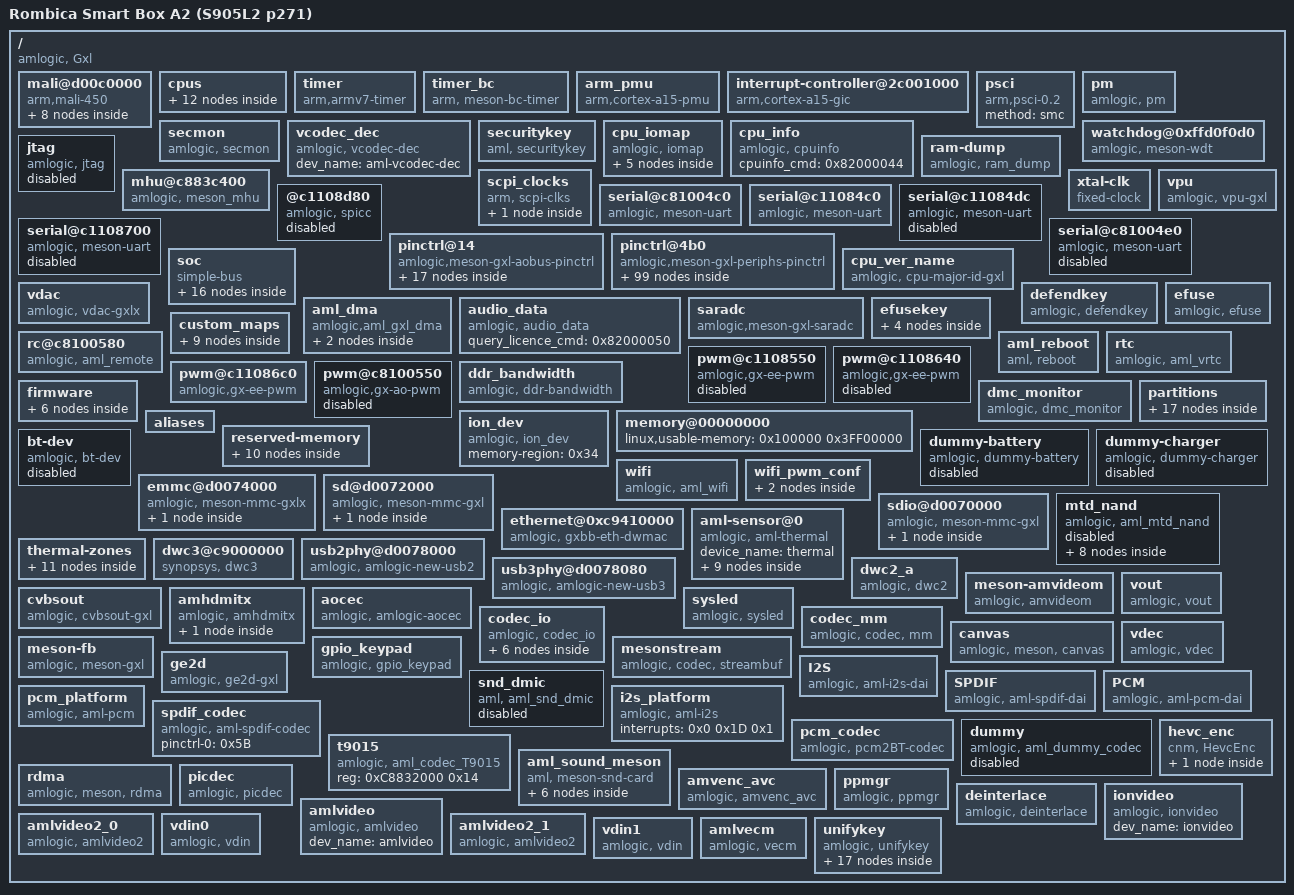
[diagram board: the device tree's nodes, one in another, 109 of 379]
/dts-v1/;
// version: 17
// last_comp_version: 16
// boot_cpuid_phys: 0x0

/ {
    amlogic-dt-id = "gxl_p212_1g";
    compatible = "amlogic, Gxl";
    interrupt-parent = <0x1>;
    #address-cells = <0x1>;
    #size-cells = <0x1>;
    model = "Rombica Smart Box A2 (S905L2 p271)";
    mali@d00c0000 {
        #cooling-cells = <0x2>;
        compatible = "arm,mali-450";
        interrupt-parent = <0x1>;
        reg = <0xD00C0000 0x40000 0xC1104440 0x1000 0xC8100000 0x1000 0xC883C000 0x1000 0xC1104440 0x1000>;
        pmu_switch_delay = <0xFFFF>;
        clocks = <0x8 0x97 0x8 0x9>;
        clock-names = "gpu_mux", "gp0_pll";
        control_interval = <0xC8>;
        phandle = <0x80>;
        num_of_pp = <0x2>;
        sc_mpp = <0x2>;
        pmu_domain_config = <0x1 0x2 0x4 0x0 0x0 0x0 0x0 0x0 0x0 0x1 0x2 0x0>;
        tbl = <0x2 0x3 0x4 0x5 0x6 0x6>;
        interrupts = <0x0 0xA0 0x4 0x0 0xA1 0x4 0x0 0xA2 0x4 0x0 0xA3 0x4 0x0 0xA4 0x4 0x0 0xA5 0x4 0x0 0xA6 0x4 0x0 0xA7 0x4>;
        interrupt-names = "IRQGP", "IRQGPMMU", "IRQPP", "IRQPMU", "IRQPP0", "IRQPPMMU0", "IRQPP1", "IRQPPMMU1";
        def_clk = <0x3>;
        clk125_cfg {
            clk_freq = <0x7735940>;
            clk_parent = "fclk_div4";
            clkp_freq = <0x1DCD6500>;
            voltage = <0x47E>;
            keep_count = <0x5>;
            threshold = <0x1E 0xFA>;
            phandle = <0x2>;
        };
        clk250_cfg {
            clk_freq = <0xEE6B280>;
            clk_parent = "fclk_div4";
            clkp_freq = <0x1DCD6500>;
            voltage = <0x47E>;
            keep_count = <0x5>;
            threshold = <0x73 0xFA>;
            phandle = <0x81>;
        };
        clk285_cfg {
            clk_freq = <0x1107A76D>;
            clk_parent = "fclk_div7";
            clkp_freq = <0x1107A76D>;
            voltage = <0x47E>;
            keep_count = <0x5>;
            threshold = <0x64 0xFA>;
            phandle = <0x3>;
        };
        clk400_cfg {
            clk_freq = <0x17D78400>;
            clk_parent = "fclk_div5";
            clkp_freq = <0x17D78400>;
            voltage = <0x47E>;
            keep_count = <0x3>;
            threshold = <0xA8 0xFA>;
            phandle = <0x4>;
        };
        clk500_cfg {
            clk_freq = <0x1DCD6500>;
            clk_parent = "fclk_div4";
            clkp_freq = <0x1DCD6500>;
            voltage = <0x47E>;
            keep_count = <0x2>;
            threshold = <0xBE 0xFA>;
            phandle = <0x5>;
        };
        clk666_cfg {
            clk_freq = <0x27BC86AA>;
            clk_parent = "fclk_div3";
            clkp_freq = <0x27BC86AA>;
            voltage = <0x47E>;
            keep_count = <0x1>;
            threshold = <0xB1 0xFA>;
            phandle = <0x6>;
        };
        clk750_cfg {
            clk_freq = <0x2C588A00>;
            clk_parent = "gp0_pll";
            clkp_freq = <0x2C588A00>;
            voltage = <0x47E>;
            keep_count = <0x1>;
            threshold = <0xD5 0xFF>;
            phandle = <0x7>;
        };
        clk800_cfg {
            clk_freq = <0x2F34F600>;
            clk_parent = "gp0_pll";
            clkp_freq = <0x2F34F600>;
            voltage = <0x47E>;
            keep_count = <0x1>;
            threshold = <0xE6 0xFF>;
            phandle = <0x82>;
        };
    };
    cpus {
        #address-cells = <0x1>;
        #size-cells = <0x0>;
        phandle = <0x83>;
        cpu-map {
            cluster0 {
                phandle = <0x84>;
                core0 {
                    cpu = <0x9>;
                };
                core1 {
                    cpu = <0xA>;
                };
                core2 {
                    cpu = <0xB>;
                };
                core3 {
                    cpu = <0xC>;
                };
            };
        };
        cpu@0 {
            device_type = "cpu";
            compatible = "arm,cortex-a53", "arm,armv8";
            reg = <0x0>;
            enable-method = "psci";
            clocks = <0xD 0x0>;
            clock-names = "cpu-cluster.0";
            cpu-idle-states = <0xE>;
            phandle = <0x9>;
        };
        cpu@1 {
            device_type = "cpu";
            compatible = "arm,cortex-a53", "arm,armv8";
            reg = <0x1>;
            enable-method = "psci";
            clocks = <0xD 0x0>;
            clock-names = "cpu-cluster.0";
            cpu-idle-states = <0xE>;
            phandle = <0xA>;
        };
        cpu@2 {
            device_type = "cpu";
            compatible = "arm,cortex-a53", "arm,armv8";
            reg = <0x2>;
            enable-method = "psci";
            clocks = <0xD 0x0>;
            clock-names = "cpu-cluster.0";
            cpu-idle-states = <0xE>;
            phandle = <0xB>;
        };
        cpu@3 {
            device_type = "cpu";
            compatible = "arm,cortex-a53", "arm,armv8";
            reg = <0x3>;
            enable-method = "psci";
            clocks = <0xD 0x0>;
            clock-names = "cpu-cluster.0";
            cpu-idle-states = <0xE>;
            phandle = <0xC>;
        };
        idle-states {
            entry-method = "arm,psci";
            system-sleep-0 {
                compatible = "arm,idle-state";
                arm,psci-suspend-param = <0x20000>;
                local-timer-stop;
                entry-latency-us = <0x3FFFFFFF>;
                exit-latency-us = <0x40000000>;
                min-residency-us = <0xFFFFFFFF>;
                phandle = <0xE>;
            };
        };
    };
    timer {
        compatible = "arm,armv7-timer";
        interrupts = <0x1 0xD 0xFF08 0x1 0xE 0xFF08 0x1 0xB 0xFF08 0x1 0xA 0xFF08>;
    };
    timer_bc {
        compatible = "arm, meson-bc-timer";
        reg = <0xC1109990 0x4 0xC1109994 0x4>;
        timer_name = "Meson TimerF";
        clockevent-rating = <0x12C>;
        clockevent-shift = <0x14>;
        clockevent-features = <0x23>;
        interrupts = <0x0 0x3C 0x1>;
        bit_enable = <0x10>;
        bit_mode = <0xC>;
        bit_resolution = <0x0>;
    };
    arm_pmu {
        compatible = "arm,cortex-a15-pmu";
        interrupts = <0x0 0x89 0x4>;
        reg = <0xC8834680 0x4>;
        cpumasks = <0xF>;
        relax-timer-ns = <0x989680>;
        max-wait-cnt = <0x2710>;
    };
    interrupt-controller@2c001000 {
        compatible = "arm,cortex-a15-gic", "arm,cortex-a9-gic";
        #interrupt-cells = <0x3>;
        #address-cells = <0x0>;
        interrupt-controller;
        reg = <0xC4301000 0x1000 0xC4302000 0x100>;
        interrupts = <0x1 0x9 0xF04>;
        phandle = <0x1>;
    };
    psci {
        compatible = "arm,psci-0.2";
        method = "smc";
    };
    pm {
        compatible = "amlogic, pm";
        device_name = "aml_pm";
        reg = <0xC81000A8 0x4 0xC810023C 0x4>;
        phandle = <0x85>;
    };
    secmon {
        compatible = "amlogic, secmon";
        memory-region = <0xF>;
        in_base_func = <0x82000020>;
        out_base_func = <0x82000021>;
        reserve_mem_size = <0x300000>;
    };
    vcodec_dec {
        compatible = "amlogic, vcodec-dec";
        dev_name = "aml-vcodec-dec";
        status = "okay";
    };
    securitykey {
        compatible = "aml, securitykey";
        storage_query = <0x82000060>;
        storage_read = <0x82000061>;
        storage_write = <0x82000062>;
        storage_tell = <0x82000063>;
        storage_verify = <0x82000064>;
        storage_status = <0x82000065>;
        storage_list = <0x82000067>;
        storage_remove = <0x82000068>;
        storage_in_func = <0x82000023>;
        storage_out_func = <0x82000024>;
        storage_block_func = <0x82000025>;
        storage_size_func = <0x82000027>;
        storage_set_enctype = <0x8200006A>;
        storage_get_enctype = <0x8200006B>;
        storage_version = <0x8200006C>;
    };
    cpu_iomap {
        compatible = "amlogic, iomap";
        #address-cells = <0x1>;
        #size-cells = <0x1>;
        ranges;
        io_cbus_base {
            reg = <0xC1100000 0x100000>;
        };
        io_apb_base {
            reg = <0xD0050000 0x50000>;
        };
        io_aobus_base {
            reg = <0xC8100000 0x100000>;
        };
        io_vapb_base {
            reg = <0xD0100000 0x100000>;
        };
        io_hiu_base {
            reg = <0xC883C000 0x2000>;
        };
    };
    cpu_info {
        compatible = "amlogic, cpuinfo";
        cpuinfo_cmd = <0x82000044>;
        status = "okay";
    };
    watchdog@0xffd0f0d0 {
        compatible = "amlogic, meson-wdt";
        status = "okay";
        default_timeout = <0xA>;
        reset_watchdog_method = <0x1>;
        reset_watchdog_time = <0x2>;
        shutdown_timeout = <0xA>;
        firmware_timeout = <0x6>;
        suspend_timeout = <0x6>;
        reg = <0xC11098D0 0x10>;
        clock-names = "xtal";
        clocks = <0x10>;
        phandle = <0x86>;
    };
    ram-dump {
        compatible = "amlogic, ram_dump";
        status = "okay";
    };
    jtag {
        compatible = "amlogic, jtag";
        select = "apao";
        jtagao-gpios = <0x11 0x16 0x0 0x11 0x17 0x0 0x11 0x18 0x0 0x11 0x19 0x0>;
        jtagee-gpios = <0x11 0x2A 0x0 0x11 0x2B 0x0 0x11 0x2C 0x0 0x11 0x2D 0x0>;
        status = "disabled";
    };
    mhu@c883c400 {
        compatible = "amlogic, meson_mhu";
        reg = <0xC883C400 0x4C 0xC8013000 0x800>;
        interrupts = <0x0 0xD1 0x1 0x0 0xD2 0x1>;
        #mbox-cells = <0x1>;
        mbox-names = "cpu_to_scp_low", "cpu_to_scp_high";
        mboxes = <0x12 0x0 0x12 0x1>;
        phandle = <0x12>;
    };
    scpi_clocks {
        compatible = "arm, scpi-clks";
        scpi_clocks@0 {
            compatible = "arm, scpi-clk-indexed";
            #clock-cells = <0x1>;
            clock-indices = <0x0>;
            clock-output-names = "vcpu";
            phandle = <0xD>;
        };
    };
    xtal-clk {
        compatible = "fixed-clock";
        clock-frequency = <0x16E3600>;
        clock-output-names = "xtal";
        #clock-cells = <0x0>;
        phandle = <0x10>;
    };
    vpu {
        compatible = "amlogic, vpu-gxl";
        dev_name = "vpu";
        status = "okay";
        clocks = <0x8 0xC4 0x8 0x59 0x8 0x9 0x8 0xB6 0x8 0xBA 0x8 0xBB>;
        clock-names = "vapb_clk", "vpu_intr_gate", "gp_pll", "vpu_clk0", "vpu_clk1", "vpu_clk";
        clk_level = <0x7>;
    };
    @c1108d80 {
        compatible = "amlogic, spicc";
        status = "disabled";
        reg = <0xC1108D80 0x28>;
        clocks = <0x8 0x1E>;
        clock-names = "spicc_clk";
        interrupts = <0x0 0x51 0x1>;
        device_id = <0x0>;
        pinctrl-names = "spicc_pulldown", "spicc_pullup";
        pinctrl-0 = <0x13>;
        pinctrl-1 = <0x14>;
        num_chipselect = <0x1>;
        cs-gpios = <0x11 0x59 0x0>;
        dma_en = <0x0>;
        dma_tx_threshold = <0x3>;
        dma_rx_threshold = <0x3>;
        dma_num_per_read_burst = <0x3>;
        dma_num_per_write_burst = <0x3>;
        delay_control = <0x15>;
        ssctl = <0x0>;
        phandle = <0x87>;
    };
    serial@c81004c0 {
        compatible = "amlogic, meson-uart";
        reg = <0xC81004C0 0x18>;
        interrupts = <0x0 0xC1 0x1>;
        status = "okay";
        clocks = <0x10>;
        clock-names = "clk_uart";
        xtal_tick_en = <0x1>;
        fifosize = <0x40>;
        pinctrl-names = "default";
        support-sysrq = <0x0>;
        phandle = <0x88>;
    };
    serial@c11084c0 {
        compatible = "amlogic, meson-uart";
        reg = <0xC11084C0 0x18>;
        interrupts = <0x0 0x1A 0x1>;
        status = "okay";
        clocks = <0x8 0x23>;
        clock-names = "clk_uart";
        fifosize = <0x80>;
        pinctrl-names = "default";
        pinctrl-0 = <0x15>;
        phandle = <0x89>;
    };
    serial@c11084dc {
        compatible = "amlogic, meson-uart";
        reg = <0xC11084DC 0x18>;
        interrupts = <0x0 0x4B 0x1>;
        status = "disabled";
        clocks = <0x8 0x40>;
        clock-names = "clk_uart";
        fifosize = <0x40>;
        pinctrl-names = "default";
        pinctrl-0 = <0x16>;
        phandle = <0x8A>;
    };
    serial@c1108700 {
        compatible = "amlogic, meson-uart";
        reg = <0xC1108700 0x18>;
        interrupts = <0x0 0x5D 0x1>;
        status = "disabled";
        clocks = <0x8 0x57>;
        clock-names = "clk_uart";
        fifosize = <0x40>;
        pinctrl-names = "default";
        pinctrl-0 = <0x17>;
        phandle = <0x8B>;
    };
    serial@c81004e0 {
        compatible = "amlogic, meson-uart";
        reg = <0xC81004E0 0x18>;
        interrupts = <0x0 0xC5 0x1>;
        status = "disable";
        clocks = <0x10>;
        clock-names = "clk_uart";
        fifosize = <0x40>;
        pinctrl-names = "default";
        pinctrl-0 = <0x18>;
        phandle = <0x8C>;
    };
    pinctrl@14 {
        compatible = "amlogic,meson-gxl-aobus-pinctrl";
        #address-cells = <0x1>;
        #size-cells = <0x1>;
        ranges;
        phandle = <0x8D>;
        bank@14 {
            reg = <0xC8100014 0x8 0xC810002C 0x4 0xC8100024 0x8>;
            reg-names = "mux", "pull", "gpio";
            gpio-controller;
            #gpio-cells = <0x2>;
            phandle = <0x57>;
        };
        remote_pin {
            phandle = <0x1E>;
            mux {
                groups = "remote_input";
                function = "remote";
            };
        };
        sd_to_ao_uart_clr_pins {
            phandle = <0x3E>;
            mux {
                groups = "GPIOAO_0", "GPIOAO_1";
                function = "gpio_aobus";
            };
        };
        sd_to_ao_uart_pins {
            phandle = <0x40>;
            mux {
                groups = "uart_tx_ao_a_0", "uart_rx_ao_a_0";
                function = "uart_ao";
                bias-pull-up;
                input-enable;
            };
        };
        ao_uart {
            phandle = <0x8E>;
            mux {
                groups = "uart_tx_ao_a_0", "uart_rx_ao_a_0";
                function = "uart_ao";
            };
        };
        ao_b_uart {
            phandle = <0x18>;
            mux {
                groups = "uart_tx_ao_b_0", "uart_rx_ao_b_0";
                function = "uart_ao_b";
            };
        };
        ao_i2c {
            phandle = <0x8F>;
            mux {
                groups = "i2c_sda_ao", "i2c_sck_ao";
                function = "i2c_ao";
            };
        };
        hdmitx_aocec {
            phandle = <0x54>;
            mux {
                groups = "ao_cec";
                function = "ao_cec";
            };
        };
        hdmitx_eecec {
            phandle = <0x90>;
            mux {
                groups = "ee_cec";
                function = "ee_cec";
            };
        };
    };
    pinctrl@4b0 {
        compatible = "amlogic,meson-gxl-periphs-pinctrl";
        #address-cells = <0x1>;
        #size-cells = <0x1>;
        ranges;
        phandle = <0x91>;
        bank@4b0 {
            reg = <0xC88344B0 0x28 0xC88344E8 0x14 0xC8834520 0x14 0xC8834430 0x40>;
            reg-names = "mux", "pull", "pull-enable", "gpio";
            gpio-controller;
            #gpio-cells = <0x2>;
            phandle = <0x11>;
        };
        external_eth_pins {
            phandle = <0x48>;
            mux {
                groups = "eth_mdio", "eth_mdc", "eth_clk_rx_clk", "eth_rx_dv", "eth_rxd0", "eth_rxd1", "eth_rxd2", "eth_rxd3", "eth_rgmii_tx_clk", "eth_tx_en", "eth_txd0", "eth_txd1", "eth_txd2", "eth_txd3";
                function = "eth";
            };
        };
        jtag_apao_pin {
            phandle = <0x92>;
            mux {
                groups = "jtag_tdi_0", "jtag_tdo_0", "jtag_clk_0", "jtag_tms_0";
                function = "jtag";
            };
        };
        jtag_apee_pin {
            phandle = <0x93>;
            mux {
                groups = "jtag_tdi_1", "jtag_tdo_1", "jtag_clk_1", "jtag_tms_1";
                function = "jtag";
            };
        };
        a_uart {
            phandle = <0x15>;
            mux {
                groups = "uart_tx_a", "uart_rx_a", "uart_cts_a", "uart_rts_a";
                function = "uart_a";
            };
        };
        b_uart {
            phandle = <0x16>;
            mux {
                groups = "uart_tx_b", "uart_rx_b", "uart_cts_b", "uart_rts_b";
                function = "uart_b";
            };
        };
        c_uart {
            phandle = <0x17>;
            mux {
                groups = "uart_tx_c", "uart_rx_c", "uart_cts_c", "uart_rts_c";
                function = "uart_c";
            };
        };
        wifi_32k_pins {
            phandle = <0x35>;
            mux {
                groups = "pwm_e";
                function = "pwm_e";
            };
        };
        ao_to_sd_uart_clr_pins {
            phandle = <0x94>;
            mux {
                groups = "sdcard_d2", "sdcard_d3";
                function = "sdcard";
                input-enable;
                bias-pull-up;
            };
        };
        sd_1bit_pins {
            phandle = <0x3D>;
            mux {
                groups = "sdcard_d0", "sdcard_cmd", "sdcard_clk";
                function = "sdcard";
                input-enable;
                bias-pull-up;
            };
        };
        ao_to_sd_uart_pins {
            phandle = <0x3F>;
            mux {
                groups = "uart_tx_ao_a_card4", "uart_rx_ao_a_card5";
                function = "uart_ao_a_card";
                bias-pull-up;
                input-enable;
            };
        };
        emmc_clk_cmd_pins {
            phandle = <0x38>;
            mux {
                groups = "emmc_cmd", "emmc_clk";
                function = "emmc";
                input-enable;
                bias-pull-up;
            };
        };
        emmc_conf_pull_up {
            phandle = <0x39>;
            mux {
                groups = "emmc_nand_d07", "emmc_clk", "emmc_cmd";
                function = "emmc";
                input-enable;
                bias-pull-up;
            };
        };
        emmc_conf_pull_done {
            phandle = <0x3A>;
            mux {
                groups = "emmc_ds";
                function = "emmc";
                input-enable;
                bias-pull-down;
            };
        };
        sd_clk_cmd_pins {
            phandle = <0x3C>;
            mux {
                groups = "sdcard_cmd", "sdcard_clk";
                function = "sdcard";
                input-enable;
                bias-pull-up;
            };
        };
        sd_all_pins {
            phandle = <0x3B>;
            mux {
                groups = "sdcard_d0", "sdcard_d1", "sdcard_d2", "sdcard_d3", "sdcard_cmd", "sdcard_clk";
                function = "sdcard";
                input-enable;
                bias-pull-up;
            };
        };
        sdio_clk_cmd_pins {
            phandle = <0x41>;
            mux {
                groups = "sdio_clk", "sdio_cmd";
                function = "sdio";
                input-enable;
                bias-pull-up;
            };
        };
        sdio_all_pins {
            phandle = <0x42>;
            mux {
                groups = "sdio_d0", "sdio_d1", "sdio_d2", "sdio_d3", "sdio_clk", "sdio_cmd";
                function = "sdio";
                input-enable;
                bias-pull-up;
            };
        };
        sd_iso7816_pins {
            phandle = <0x95>;
            mux {
                groups = "iso7816_clk_dv", "iso7816_data_dv";
                function = "iso7816";
                input-enable;
                bias-pull-down;
            };
        };
        nand_pulldown {
            phandle = <0x96>;
            mux {
                groups = "emmc_nand_d07", "emmc_ds";
                function = "emmc";
                bias-pull-down;
            };
        };
        nand_pullup {
            phandle = <0x97>;
            mux {
                groups = "emmc_clk", "emmc_cmd";
                function = "emmc";
                bias-pull-up;
            };
        };
        all_nand_pins {
            phandle = <0x43>;
            mux {
                groups = "emmc_nand_d07", "nand_ce0", "nand_ce1", "nand_rb0", "nand_ale", "nand_cle", "nand_wen_clk", "nand_ren_wr", "nand_dqs";
                function = "nand";
                input-enable;
            };
        };
        nand_cs {
            phandle = <0x44>;
            mux {
                groups = "nand_ce0", "nand_ce1";
                function = "nand";
            };
        };
        hdmitx_hpd {
            phandle = <0x52>;
            mux {
                groups = "hdmi_hpd";
                function = "hdmi_hpd";
            };
        };
        hdmitx_ddc {
            phandle = <0x53>;
            mux {
                groups = "hdmi_sda", "hdmi_scl";
                function = "hdmi_ddc";
            };
        };
        a_i2c {
            phandle = <0x98>;
            mux {
                groups = "i2c_sda_a", "i2c_scl_a";
                function = "i2c_a";
            };
        };
        b_i2c {
            phandle = <0x99>;
            mux {
                groups = "i2c_sda_b", "i2c_scl_b";
                function = "i2c_b";
            };
        };
        c_i2c {
            phandle = <0x9A>;
            mux {
                groups = "i2c_sda_c_dv28", "i2c_scl_c_dv29";
                function = "i2c_c";
            };
        };
        c_i2c_pin1 {
            phandle = <0x9B>;
            mux {
                groups = "i2c_sda_c_dv18", "i2c_scl_c_dv19";
                function = "i2c_c";
            };
        };
        d_i2c {
            phandle = <0x9C>;
            mux {
                groups = "i2c_sda_d", "i2c_scl_d";
                function = "i2c_d";
            };
        };
        spicc_pulldown_z11z12z13 {
            phandle = <0x9D>;
            mux {
                groups = "spi_sclk_0", "spi_miso_0", "spi_mosi_0";
                function = "spi";
            };
        };
        spicc_pullup_z11z12z13 {
            phandle = <0x9E>;
            mux {
                groups = "spi_sclk_0", "spi_miso_0", "spi_mosi_0";
                function = "spi";
            };
        };
        spicc_pulldown_x8x9x11 {
            phandle = <0x13>;
            mux {
                groups = "spi_sclk_1", "spi_miso_1", "spi_mosi_1";
                function = "spi";
                bias-pull-down;
            };
        };
        spicc_pullup_x8x9x11 {
            phandle = <0x14>;
            mux {
                groups = "spi_sclk_1", "spi_miso_1", "spi_mosi_1";
                function = "spi";
                bias-pull-up;
            };
        };
        audio_i2s {
            phandle = <0x5C>;
            mux {
                groups = "i2s_am_clk", "i2s_ao_clk_out", "i2s_lr_clk_out", "i2sout_ch01";
                function = "i2s";
            };
        };
        audio_spdif {
            phandle = <0x5B>;
            mux {
                groups = "spdif_out";
                function = "spdif_out";
            };
        };
        audio_spdif_in {
            phandle = <0x9F>;
            mux {
                groups = "spdif_in_z14";
                function = "spdif_in";
            };
        };
        audio_spdif_in_1 {
            phandle = <0xA0>;
            mux {
                groups = "spdif_in_h4";
                function = "spdif_in";
            };
        };
        audio_pcm {
            phandle = <0x5A>;
            mux {
                groups = "pcm_out_a", "pcm_in_a", "pcm_fs_a", "pcm_clk_a";
                function = "pcm_a";
            };
        };
        audio_dmic {
            phandle = <0x59>;
            mux {
                groups = "dmic_in_dv24", "dmic_clk_dv25";
                function = "dmic";
            };
        };
        dvb_p_ts0_pins {
            phandle = <0xA1>;
            tsin_a {
                groups = "tsin_sop_a_dv9", "tsin_d_valid_a_dv10", "tsin_d0_a_dv0", "tsin_d1_7_a_dv1_7", "tsin_clk_a_dv8";
                function = "tsin_a";
            };
        };
        dvb_s_ts0_pins {
            phandle = <0xA2>;
            tsin_a {
                groups = "tsin_sop_a_dv9", "tsin_d_valid_a_dv10", "tsin_clk_a_dv8", "tsin_d0_a_dv0";
                function = "tsin_a";
            };
        };
        lcd_ttl_rgb_6bit_on {
            phandle = <0xA3>;
            mux {
                groups = "lcd_r2_7", "lcd_g2_7", "lcd_b2_7";
                function = "lcd_ttl";
            };
        };
        lcd_ttl_rgb_6bit_off {
            phandle = <0xA4>;
            mux {
                groups = "GPIODV_2", "GPIODV_3", "GPIODV_4", "GPIODV_5", "GPIODV_6", "GPIODV_7", "GPIODV_10", "GPIODV_11", "GPIODV_12", "GPIODV_13", "GPIODV_14", "GPIODV_15", "GPIODV_18", "GPIODV_19", "GPIODV_20", "GPIODV_21", "GPIODV_22", "GPIODV_23";
                function = "gpio_periphs";
                input-enable;
            };
        };
        lcd_ttl_rgb_8bit_on {
            phandle = <0xA5>;
            mux {
                groups = "lcd_r0_1", "lcd_r2_7", "lcd_g0_1", "lcd_g2_7", "lcd_b0_1", "lcd_b2_7";
                function = "lcd_ttl";
            };
        };
        lcd_ttl_rgb_8bit_off {
            phandle = <0xA6>;
            mux {
                groups = "GPIODV_0", "GPIODV_1", "GPIODV_2", "GPIODV_3", "GPIODV_4", "GPIODV_5", "GPIODV_6", "GPIODV_7", "GPIODV_8", "GPIODV_9", "GPIODV_10", "GPIODV_11", "GPIODV_12", "GPIODV_13", "GPIODV_14", "GPIODV_15", "GPIODV_16", "GPIODV_17", "GPIODV_18", "GPIODV_19", "GPIODV_20", "GPIODV_21", "GPIODV_22", "GPIODV_23";
                function = "gpio_periphs";
                input-enable;
            };
        };
        lcd_ttl_de_on_pin {
            phandle = <0xA7>;
            mux {
                groups = "tcon_cph", "tcon_oeh";
                function = "lcd_ttl";
            };
        };
        lcd_ttl_hvsync_on_pin {
            phandle = <0xA8>;
            mux {
                groups = "tcon_cph", "tcon_stv1", "tcon_sth1";
                function = "lcd_ttl";
            };
        };
        lcd_ttl_de_hvsync_on_pin {
            phandle = <0xA9>;
            mux {
                groups = "tcon_cph", "tcon_oeh", "tcon_stv1", "tcon_sth1";
                function = "lcd_ttl";
            };
        };
        lcd_ttl_de_hvsync_off_pin {
            phandle = <0xAA>;
            mux {
                groups = "GPIODV_26", "GPIODV_27", "GPIODV_24", "GPIODV_25";
                function = "gpio_periphs";
                input-enable;
            };
        };
    };
    soc {
        compatible = "simple-bus";
        #address-cells = <0x1>;
        #size-cells = <0x1>;
        ranges;
        cbus@c1100000 {
            compatible = "simple-bus";
            reg = <0xC1100000 0x100000>;
            #address-cells = <0x1>;
            #size-cells = <0x1>;
            ranges = <0x0 0xC1100000 0x100000>;
            phandle = <0xAB>;
            interrupt-controller@9880 {
                compatible = "amlogic,meson-gpio-intc", "amlogic,meson-gxl-gpio-intc";
                reg = <0x9880 0x10>;
                interrupt-controller;
                #interrupt-cells = <0x2>;
                amlogic,channel-interrupts = <0x40 0x41 0x42 0x43 0x44 0x45 0x46 0x47>;
                status = "okay";
                phandle = <0xAC>;
            };
            meson_clk_msr {
                compatible = "amlogic, gxl_measure";
                reg = <0x875C 0x4 0x8764 0x4>;
            };
            i2c@8500 {
                compatible = "amlogic,meson-gx-i2c";
                status = "disabled";
                reg = <0x8500 0x20>;
                interrupts = <0x0 0x15 0x1 0x0 0x2F 0x1>;
                #address-cells = <0x1>;
                #size-cells = <0x0>;
                clocks = <0x8 0x1F>;
                clock-names = "clk_i2c";
                phandle = <0xAD>;
            };
            i2c@87c0 {
                compatible = "amlogic,meson-gx-i2c";
                status = "disabled";
                reg = <0x87C0 0x20>;
                interrupts = <0x0 0xD6 0x1 0x0 0x30 0x1>;
                #address-cells = <0x1>;
                #size-cells = <0x0>;
                clocks = <0x8 0x1F>;
                clock-names = "clk_i2c";
                phandle = <0xAE>;
            };
            i2c@87e0 {
                compatible = "amlogic,meson-gx-i2c";
                status = "disabled";
                reg = <0x87E0 0x20>;
                interrupts = <0x0 0xD7 0x1 0x0 0x31 0x1>;
                #address-cells = <0x1>;
                #size-cells = <0x0>;
                clocks = <0x8 0x1F>;
                clock-names = "clk_i2c";
                phandle = <0xAF>;
            };
            i2c@8d20 {
                compatible = "amlogic,meson-gx-i2c";
                status = "disabled";
                reg = <0x8D20 0x20>;
                interrupts = <0x0 0x27 0x1 0x0 0x32 0x1>;
                #address-cells = <0x1>;
                #size-cells = <0x0>;
                clocks = <0x8 0x1F>;
                clock-names = "clk_i2c";
                phandle = <0xB0>;
            };
            reset-controller@4404 {
                compatible = "amlogic,reset";
                reg = <0x4404 0x20>;
                #reset-cells = <0x1>;
                phandle = <0xB1>;
            };
        };
        aobus@c8100000 {
            compatible = "simple-bus";
            reg = <0xC8100000 0x100000>;
            #address-cells = <0x1>;
            #size-cells = <0x1>;
            ranges = <0x0 0xC8100000 0x100000>;
            phandle = <0xB2>;
            cpu_version {
                reg = <0xA8 0x4>;
            };
            i2c@0500 {
                compatible = "amlogic,meson-gx-i2c";
                status = "disabled";
                reg = <0x500 0x20>;
                interrupts = <0x0 0xC3 0x1>;
                #address-cells = <0x1>;
                #size-cells = <0x0>;
                clocks = <0x8 0x1F>;
                clock-names = "clk_i2c";
                phandle = <0xB3>;
            };
        };
        periphs@c8834000 {
            compatible = "simple-bus";
            reg = <0xC8834000 0x2000>;
            #address-cells = <0x1>;
            #size-cells = <0x1>;
            ranges = <0x0 0xC8834000 0x2000>;
            phandle = <0xB4>;
            rng {
                compatible = "amlogic,meson-rng";
                reg = <0x0 0x4>;
                quality = [03 E8];
            };
        };
        hiubus@c883c000 {
            compatible = "simple-bus";
            reg = <0xC883C000 0x2000>;
            #address-cells = <0x1>;
            #size-cells = <0x1>;
            ranges = <0x0 0xC883C000 0x2000>;
            phandle = <0xB5>;
            clock-controller@0 {
                compatible = "amlogic,gxl-clkc";
                #clock-cells = <0x1>;
                reg = <0x0 0x3DB>;
                phandle = <0x8>;
            };
        };
        apb@d0000000 {
            compatible = "simple-bus";
            reg = <0xD0000000 0x200000>;
            #address-cells = <0x1>;
            #size-cells = <0x1>;
            ranges = <0x0 0xD0000000 0x200000>;
            phandle = <0xB6>;
        };
    };
    cpu_ver_name {
        compatible = "amlogic, cpu-major-id-gxl";
    };
    vdac {
        status = "okay";
        compatible = "amlogic, vdac-gxlx";
    };
    defendkey {
        compatible = "amlogic, defendkey";
        reg = <0xC8834500 0x4>;
        mem_size = <0x0 0x100000>;
        status = "okay";
        phandle = <0xB7>;
    };
    aml_dma {
        compatible = "amlogic,aml_gxl_dma";
        reg = <0xC883E000 0x28>;
        interrupts = <0x0 0xBC 0x1>;
        aml_aes {
            compatible = "amlogic,aes_dma";
            dev_name = "aml_aes_dma";
            status = "okay";
        };
        aml_tdes {
            compatible = "amlogic,des_dma,tdes_dma";
            dev_name = "aml_tdes_dma";
            status = "okay";
        };
    };
    audio_data {
        compatible = "amlogic, audio_data";
        query_licence_cmd = <0x82000050>;
        status = "okay";
        phandle = <0xB8>;
    };
    saradc {
        compatible = "amlogic,meson-gxl-saradc";
        status = "okay";
        #io-channel-cells = <0x1>;
        clocks = <0x10 0x8 0x58 0x8 0xE4>;
        clock-names = "xtal", "clk81_gate", "saradc_clk";
        interrupts = <0x0 0x49 0x1>;
        reg = <0xC1108680 0x38>;
        phandle = <0xB9>;
    };
    efuse {
        compatible = "amlogic, efuse";
        read_cmd = <0x82000030>;
        write_cmd = <0x82000031>;
        get_max_cmd = <0x82000033>;
        key = <0x19>;
        clocks = <0x8 0x4A>;
        clock-names = "efuse_clk";
        status = "ok";
        phandle = <0xBA>;
    };
    efusekey {
        keynum = <0x4>;
        key0 = <0x1A>;
        key1 = <0x1B>;
        key2 = <0x1C>;
        key3 = <0x1D>;
        phandle = <0x19>;
        key_0 {
            keyname = "mac";
            offset = <0x0>;
            size = <0x6>;
            phandle = <0x1A>;
        };
        key_1 {
            keyname = "mac_bt";
            offset = <0x6>;
            size = <0x6>;
            phandle = <0x1B>;
        };
        key_2 {
            keyname = "mac_wifi";
            offset = <0xC>;
            size = <0x6>;
            phandle = <0x1C>;
        };
        key_3 {
            keyname = "usid";
            offset = <0x12>;
            size = <0x10>;
            phandle = <0x1D>;
        };
    };
    rc@c8100580 {
        compatible = "amlogic, aml_remote";
        dev_name = "meson-remote";
        reg = <0xC8100580 0x44 0xC8100480 0x20>;
        status = "okay";
        protocol = <0x1>;
        interrupts = <0x0 0xC4 0x1>;
        pinctrl-names = "default";
        pinctrl-0 = <0x1E>;
        map = <0x1F>;
        max_frame_time = <0xC8>;
        phandle = <0xBB>;
    };
    custom_maps {
        map0 = <0x20>;
        map1 = <0x21>;
        map2 = <0x22>;
        phandle = <0x1F>;
        map3 = <0xCF>;
        map4 = <0xD0>;
        map5 = <0xD1>;
        map6 = <0xD2>;
        map7 = <0xD3>;
        map8 = <0xD4>;
        mapnum = <0x9>;
        map_0 {
            mapname = "amlogic-remote-1";
            customcode = <0x1B04>;
            release_delay = <0x50>;
            size = <0x32>;
            keymap = <0x47000B 0x130002 0x100003 0x110004 0xF0005 0xC0006 0xD0007 0xB0008 0x80009 0x9000A 0x5C0061 0x51003D 0x50003E 0x40003F 0x4D0040 0x430041 0x170042 0x43 0x10044 0x160057 0x49000E 0x60082 0x140083 0x440067 0x1D006C 0x1C0069 0x48006A 0x53007D 0x450068 0x19006D 0x520077 0x5007A 0x59007B 0x1B0078 0x40079 0x1A0074 0xA000F 0xE0071 0x1F0066 0x1E0084 0x70085 0x120086 0x540087 0x20088 0x4F001E 0x420030 0x5D002E 0x4C0020 0x580089 0x55008C>;
            phandle = <0x20>;
        };
        map_1 {
            mapname = "amlogic-remote-2";
            customcode = <0x1E01>;
            release_delay = <0x50>;
            size = <0x35>;
            keymap = <0x10002 0x20003 0x30004 0x40005 0x50006 0x60007 0x70008 0x80009 0x9000A 0xA000B 0x1F01D2 0x15008B 0x16000F 0xC0192 0xD0193 0xE0073 0xF0072 0x110066 0x1C006A 0x1B0069 0x190067 0x1A006C 0x1D001C 0x170071 0x4900DB 0x43009E 0x1201D5 0x1401D6 0x1801D7 0x590166 0x5A00A6 0x100074 0x4200A5 0x4400A3 0x1E00A8 0x4B00D0 0x5800A4 0x460082 0x400083 0x380046 0x5701D0 0x5B01D1 0x54018E 0x4C018F 0x4E0190 0x550191 0x5300ED 0x5200EE 0x3900D4 0x4100D5 0xB00D6 0xD8 0x1300D9>;
            phandle = <0x21>;
        };
        map_2 {
            mapname = "amlogic-remote-3";
            customcode = <0x1D02>;
            release_delay = <0x50>;
            size = <0x11>;
            keymap = <0xCA0067 0xD2006C 0x990069 0xC1006A 0xCE0061 0x450074 0xC50085 0x800071 0xD0000F 0xD6007D 0x950066 0xDD0068 0x8C006D 0x890083 0x9C0082 0x9A0078 0xCD0079>;
            phandle = <0x22>;
        };
        map_3 {
            mapname = "cyxtech-remote-a95x";
            customcode = <0xDF00>;
            release_delay = <0x50>;
            size = <0x1B>;
            keymap = <0xC000B 0x540002 0x160003 0x150004 0x500005 0x120006 0x110007 0x4C0008 0xE0009 0xD000A 0x10000E 0x1A0067 0x48006C 0x470069 0x7006A 0x60061 0x4B007A 0x4F007B 0x1C0074 0x420066 0xA009E 0x18008B 0x5D0073 0x5C0072 0x410046 0x10186 0x5F018A>;
            phandle = <0xCF>;
        };
        map_4 {
            mapname = "cyxtech-remote-cs918";
            customcode = <0x4040>;
            release_delay = <0x50>;
            size = <0x1D>;
            keymap = <0xB 0x10002 0x20003 0x30004 0x40005 0x50006 0x60007 0x70008 0x80009 0x9000A 0xC000E 0xB0067 0xE006C 0x100069 0x11006A 0xD0061 0x1E007A 0x1F007B 0x4D0074 0x1A0066 0x42009E 0x45008B 0x150073 0x1C0072 0x430071 0x570046 0x5B018B 0x540188 0x530189>;
            phandle = <0xD0>;
        };
        map_5 {
            mapname = "cyxtech-remote-8200";
            customcode = <0xFE01>;
            release_delay = <0x50>;
            size = <0x1B>;
            keymap = <0x1000B 0x4E0002 0xD0003 0xC0004 0x4A0005 0x90006 0x80007 0x460008 0x50009 0x4000A 0x42000E 0x160067 0x1A006C 0x510069 0x50006A 0x130061 0x4B007A 0x4F007B 0x400074 0x110066 0x19009E 0x8B 0x180073 0x100072 0x410046 0xF0186 0x43018A>;
            phandle = <0xD1>;
        };
        map_6 {
            mapname = "cyxtech-remote-test";
            customcode = <0xDF20>;
            release_delay = <0x50>;
            size = <0xC>;
            keymap = <0x410000 0x500000 0x420000 0x1A0000 0x1B0000 0x4F0000 0x430000 0x140000 0x4D0000 0x5A0190 0x560191 0x510192>;
            phandle = <0xD2>;
        };
        map_7 {
            mapname = "cyxtech-remote-test2";
            customcode = <0xFF00>;
            release_delay = <0x50>;
            size = <0x9>;
            keymap = <0x470190 0x460191 0x450192 0x4A0000 0x4B0000 0x490000 0x4E0000 0x4F0000 0x4D0000>;
            phandle = <0xD3>;
        };
        map_8 {
            mapname = "remote_mouse_r2a";
            customcode = <0x7F80>;
            release_delay = <0x50>;
            size = <0xC>;
            keymap = <0x810074 0x890072 0x870073 0x730066 0x83008B 0x380067 0x40006C 0x370069 0x39006A 0x130061 0x27009E 0x480184>;
            phandle = <0xD4>;
        };
    };
    aml_reboot {
        compatible = "aml, reboot";
        sys_reset = <0x84000009>;
        sys_poweroff = <0x84000008>;
    };
    rtc {
        compatible = "amlogic, aml_vrtc";
        alarm_reg_addr = <0xC81000A8>;
        timer_e_addr = <0xC1109988>;
        init_date = "2017/01/01";
        status = "okay";
    };
    pwm@c1108550 {
        compatible = "amlogic,gx-ee-pwm";
        reg = <0xC1108550 0x1C>;
        #pwm-cells = <0x3>;
        clocks = <0x10 0x10 0x10 0x10>;
        clock-names = "clkin0", "clkin1", "clkin2", "clkin3";
        status = "disabled";
        phandle = <0xBC>;
    };
    pwm@c1108640 {
        compatible = "amlogic,gx-ee-pwm";
        reg = <0xC1108640 0x1C>;
        #pwm-cells = <0x3>;
        clocks = <0x10 0x10 0x10 0x10>;
        clock-names = "clkin0", "clkin1", "clkin2", "clkin3";
        status = "disabled";
        phandle = <0xBD>;
    };
    pwm@c11086c0 {
        compatible = "amlogic,gx-ee-pwm";
        reg = <0xC11086C0 0x1C>;
        #pwm-cells = <0x3>;
        clocks = <0x10 0x10 0x10 0x10>;
        clock-names = "clkin0", "clkin1", "clkin2", "clkin3";
        status = "okay";
        phandle = <0x37>;
    };
    pwm@c8100550 {
        compatible = "amlogic,gx-ao-pwm";
        reg = <0xC8100550 0x1C>;
        #pwm-cells = <0x3>;
        clocks = <0x10 0x10 0x10 0x10>;
        clock-names = "clkin0", "clkin1", "clkin2", "clkin3";
        status = "disabled";
        phandle = <0xBE>;
    };
    ddr_bandwidth {
        compatible = "amlogic, ddr-bandwidth";
        status = "okay";
        reg = <0xC8838000 0x100 0xC8837000 0x100>;
        interrupts = <0x0 0x34 0x1>;
        interrupt-names = "ddr_bandwidth";
    };
    dmc_monitor {
        compatible = "amlogic, dmc_monitor";
        status = "okay";
        reg_base = <0xDA838400>;
        interrupts = <0x0 0x33 0x1>;
    };
    firmware {
        android {
            compatible = "android,firmware";
            vbmeta {
                compatible = "android,vbmeta";
                parts = "vbmeta,boot,system,vendor";
                by_name_prefix = "/dev/block";
            };
            fstab {
                compatible = "android,fstab";
                vendor {
                    compatible = "android,vendor";
                    dev = "/dev/block/vendor";
                    type = "ext4";
                    mnt_flags = "ro,barrier=1,inode_readahead_blks=8";
                    fsmgr_flags = "wait";
                };
                product {
                    compatible = "android,product";
                    dev = "/dev/block/product";
                    type = "ext4";
                    mnt_flags = "ro,barrier=1,inode_readahead_blks=8";
                    fsmgr_flags = "wait";
                };
                odm {
                    compatible = "android,odm";
                    dev = "/dev/block/odm";
                    type = "ext4";
                    mnt_flags = "ro,barrier=1,inode_readahead_blks=8";
                    fsmgr_flags = "wait";
                };
            };
        };
    };
    partitions {
        parts = <0x11>;
        part-0 = <0x23>;
        part-1 = <0x24>;
        part-2 = <0x25>;
        part-3 = <0x26>;
        part-4 = <0x27>;
        part-5 = <0x28>;
        part-6 = <0x29>;
        part-7 = <0x2A>;
        part-8 = <0x2B>;
        part-9 = <0x2C>;
        part-10 = <0x2D>;
        part-11 = <0x2E>;
        part-12 = <0x2F>;
        part-13 = <0x30>;
        part-14 = <0x31>;
        part-15 = <0x32>;
        part-16 = <0x33>;
        phandle = <0xBF>;
        logo {
            pname = "logo";
            size = <0x0 0x800000>;
            mask = <0x1>;
            phandle = <0x23>;
        };
        recovery {
            pname = "recovery";
            size = <0x0 0x1800000>;
            mask = <0x1>;
            phandle = <0x24>;
        };
        misc {
            pname = "misc";
            size = <0x0 0x800000>;
            mask = <0x1>;
            phandle = <0x25>;
        };
        dtbo {
            pname = "dtbo";
            size = <0x0 0x800000>;
            mask = <0x1>;
            phandle = <0x26>;
        };
        cri_data {
            pname = "cri_data";
            size = <0x0 0x800000>;
            mask = <0x2>;
            phandle = <0x27>;
        };
        rsv {
            pname = "rsv";
            size = <0x0 0x1000000>;
            mask = <0x1>;
            phandle = <0x2A>;
        };
        metadata {
            pname = "metadata";
            size = <0x0 0x1000000>;
            mask = <0x1>;
            phandle = <0x2B>;
        };
        vbmeta {
            pname = "vbmeta";
            size = <0x0 0x200000>;
            mask = <0x1>;
            phandle = <0x2C>;
        };
        param {
            pname = "param";
            size = <0x0 0x1000000>;
            mask = <0x2>;
            phandle = <0x28>;
        };
        boot {
            pname = "boot";
            size = <0x0 0x1000000>;
            mask = <0x1>;
            phandle = <0x29>;
        };
        tee {
            pname = "tee";
            size = <0x0 0x2000000>;
            mask = <0x1>;
            phandle = <0x2D>;
        };
        vendor {
            pname = "vendor";
            size = <0x0 0x14000000>;
            mask = <0x1>;
            phandle = <0x2E>;
        };
        odm {
            pname = "odm";
            size = <0x0 0x8000000>;
            mask = <0x1>;
            phandle = <0x2F>;
        };
        system {
            pname = "system";
            size = <0x0 0x50000000>;
            mask = <0x1>;
            phandle = <0x30>;
        };
        product {
            pname = "product";
            size = <0x0 0x8000000>;
            mask = <0x1>;
            phandle = <0x31>;
        };
        cache {
            pname = "cache";
            size = <0x0 0x46000000>;
            mask = <0x2>;
            phandle = <0x32>;
        };
        data {
            pname = "data";
            size = <0xFFFFFFFF 0xFFFFFFFF>;
            mask = <0x4>;
            phandle = <0x33>;
        };
    };
    aliases {
        serial0 = "/serial@c81004c0";
        serial1 = "/serial@c11084c0";
        serial2 = "/serial@c11084dc";
        serial3 = "/serial@c1108700";
        serial4 = "/serial@c81004e0";
    };
    ion_dev {
        compatible = "amlogic, ion_dev";
        memory-region = <0x34>;
    };
    memory@00000000 {
        device_type = "memory";
        linux,usable-memory = <0x100000 0x3FF00000>;
    };
    reserved-memory {
        #address-cells = <0x1>;
        #size-cells = <0x1>;
        ranges;
        linux,secmon {
            compatible = "shared-dma-pool";
            reusable;
            size = <0x400000>;
            alignment = <0x400000>;
            alloc-ranges = <0x5000000 0x400000>;
            phandle = <0xF>;
        };
        linux,secos {
            status = "disable";
            compatible = "amlogic, aml_secos_memory";
            reg = <0x5300000 0x2000000>;
            no-map;
            phandle = <0xC0>;
        };
        linux,meson-fb {
            compatible = "shared-dma-pool";
            reusable;
            size = <0x800000>;
            alignment = <0x400000>;
            alloc-ranges = <0x3F800000 0x800000>;
            phandle = <0x58>;
        };
        linux,codec_mm_cma {
            compatible = "shared-dma-pool";
            reusable;
            size = <0xD000000>;
            alignment = <0x400000>;
            linux,contiguous-region;
            alloc-ranges = <0x30000000 0x10000000>;
            phandle = <0x55>;
        };
        linux,di_cma {
            compatible = "shared-dma-pool";
            reusable;
            size = <0x2000000>;
            alignment = <0x400000>;
            alloc-ranges = <0x30000000 0x10000000>;
            phandle = <0x6D>;
        };
        linux,ion-dev {
            compatible = "shared-dma-pool";
            reusable;
            size = <0x4C00000>;
            alignment = <0x400000>;
            alloc-ranges = <0x0 0x30000000>;
            phandle = <0x34>;
        };
        linux,vdin1_cma {
            compatible = "shared-dma-pool";
            reusable;
            size = <0x1000000>;
            alignment = <0x400000>;
            alloc-ranges = <0x0 0x30000000>;
            phandle = <0x6E>;
        };
        linux,ppmgr {
            compatible = "shared-dma-pool";
            size = <0x0>;
            phandle = <0x6C>;
        };
        linux,picdec {
            compatible = "shared-dma-pool";
            reusable;
            size = <0x0>;
            alignment = <0x0>;
            linux,contiguous-region;
            phandle = <0x6B>;
        };
        linux,codec_mm_reserved {
            compatible = "amlogic, codec-mm-reserved";
            size = <0x0>;
            alignment = <0x100000>;
            phandle = <0x56>;
        };
    };
    dummy-battery {
        compatible = "amlogic, dummy-battery";
        status = "disabled";
        phandle = <0xC1>;
    };
    dummy-charger {
        compatible = "amlogic, dummy-charger";
        status = "disabled";
        phandle = <0xC2>;
    };
    bt-dev {
        compatible = "amlogic, bt-dev";
        dev_name = "bt-dev";
        gpio_reset = <0x11 0x60 0x0>;
        status = "disabled";
    };
    wifi {
        compatible = "amlogic, aml_wifi";
        dev_name = "aml_wifi";
        status = "okay";
        interrupt_pin = <0x11 0x56 0x0>;
        dhd_static_buf;
        power_on_pin = <0x11 0x55 0x0>;
        pinctrl-names = "default";
        pinctrl-0 = <0x35>;
        pwm_config = <0x36>;
        irq_trigger_type = "GPIO_IRQ_HIGH";
    };
    wifi_pwm_conf {
        phandle = <0x36>;
        pwm_channel1_conf {
            pwms = <0x37 0x0 0x774D 0x0>;
            duty-cycle = <0x3BA6>;
            times = <0x8>;
        };
        pwm_channel2_conf {
            pwms = <0x37 0x2 0x7724 0x0>;
            duty-cycle = <0x3B92>;
            times = <0xC>;
        };
    };
    emmc@d0074000 {
        status = "okay";
        reg = <0xD0074000 0x2000>;
        interrupts = <0x0 0xDA 0x1>;
        pinctrl-names = "emmc_clk_cmd_pins", "emmc_all_pins";
        pinctrl-0 = <0x38>;
        pinctrl-1 = <0x39 0x3A>;
        clocks = <0x8 0x2E 0x8 0x82 0x8 0x4>;
        clock-names = "core", "clkin0", "clkin1";
        bus-width = <0x8>;
        cap-sd-highspeed;
        cap-mmc-highspeed;
        mmc-ddr-1_8v;
        mmc-hs200-1_8v;
        max-frequency = <0xBEBC200>;
        non-removable;
        disable-wp;
        phandle = <0xC3>;
        compatible = "amlogic, meson-mmc-gxlx";
        emmc {
            pinname = "emmc";
            ocr_avail = <0x200080>;
            caps = "MMC_CAP_8_BIT_DATA", "MMC_CAP_MMC_HIGHSPEED", "MMC_CAP_SD_HIGHSPEED", "MMC_CAP_NONREMOVABLE", "MMC_CAP_1_8V_DDR", "MMC_CAP_HW_RESET", "MMC_CAP_ERASE", "MMC_CAP_CMD23";
            f_min = <0x61A80>;
            f_max = <0x5F5E100>;
            max_req_size = <0x20000>;
            gpio_dat3 = <0x11 0x1D 0x0>;
            hw_reset = <0x11 0x23 0x0>;
            card_type = <0x1>;
            caps2 = "MMC_CAP2_HS200";
        };
    };
    sd@d0072000 {
        status = "okay";
        compatible = "amlogic, meson-mmc-gxl";
        reg = <0xD0072000 0x2000>;
        interrupts = <0x0 0xD9 0x1>;
        pinctrl-names = "sd_all_pins", "sd_clk_cmd_pins", "sd_1bit_pins", "sd_clk_cmd_uart_pins", "sd_1bit_uart_pins", "sd_to_ao_uart_pins", "ao_to_sd_uart_pins", "ao_to_sd_jtag_pins", "sd_to_ao_jtag_pins";
        pinctrl-0 = <0x3B>;
        pinctrl-1 = <0x3C>;
        pinctrl-2 = <0x3D>;
        pinctrl-3 = <0x3E 0x3C 0x3F>;
        pinctrl-4 = <0x3E 0x3D 0x3F>;
        pinctrl-5 = <0x3B 0x40>;
        pinctrl-6 = <0x3E 0x3F>;
        pinctrl-7 = <0x3E 0x3F>;
        pinctrl-8 = <0x3B 0x40>;
        clocks = <0x8 0x2D 0x8 0x7E 0x8 0x4>;
        clock-names = "core", "clkin0", "clkin1";
        bus-width = <0x4>;
        disable-wp;
        phandle = <0xC4>;
        max-frequency = <0x17D7840>;
        sd {
            pinname = "sd";
            ocr_avail = <0x200080>;
            f_min = <0x61A80>;
            max_req_size = <0x20000>;
            gpio_dat3 = <0x11 0x2E 0x0>;
            jtag_pin = <0x11 0x2A 0x0>;
            gpio_cd = <0x11 0x30 0x0>;
            card_type = <0x5>;
            caps = "MMC_CAP_4_BIT_DATA";
            f_max = <0x17D7840>;
        };
    };
    sdio@d0070000 {
        status = "okay";
        compatible = "amlogic, meson-mmc-gxl";
        reg = <0xD0070000 0x2000>;
        interrupts = <0x0 0xD8 0x4>;
        pinctrl-names = "sdio_clk_cmd_pins", "sdio_all_pins";
        pinctrl-0 = <0x41>;
        pinctrl-1 = <0x42>;
        clocks = <0x8 0x2C 0x8 0x7A 0x8 0x4>;
        clock-names = "core", "clkin0", "clkin1";
        bus-width = <0x4>;
        cap-sd-highspeed;
        cap-mmc-highspeed;
        max-frequency = <0x5F5E100>;
        non-removable;
        disable-wp;
        phandle = <0xC5>;
        sdio {
            pinname = "sdio";
            ocr_avail = <0x200080>;
            caps = "MMC_CAP_4_BIT_DATA", "MMC_CAP_MMC_HIGHSPEED", "MMC_CAP_SD_HIGHSPEED", "MMC_CAP_NONREMOVABLE", "MMC_CAP_UHS_SDR12", "MMC_CAP_UHS_SDR25", "MMC_CAP_UHS_SDR50", "MMC_CAP_UHS_SDR104", "MMC_PM_KEEP_POWER", "MMC_CAP_SDIO_IRQ";
            f_min = <0x61A80>;
            f_max = <0xBEBC200>;
            max_req_size = <0x20000>;
            card_type = <0x3>;
        };
    };
    mtd_nand {
        compatible = "amlogic, aml_mtd_nand";
        dev_name = "mtdnand";
        status = "disabled";
        reg = <0xD0074800 0x200>;
        interrupts = <0x0 0x22 0x1>;
        pinctrl-names = "nand_rb_mod", "nand_norb_mod", "nand_cs_only";
        pinctrl-0 = <0x43>;
        pinctrl-1 = <0x43>;
        pinctrl-2 = <0x44>;
        device_id = <0x0>;
        plat-names = "bootloader", "nandnormal";
        plat-num = <0x2>;
        plat-part-0 = <0x45>;
        plat-part-1 = <0x46>;
        bootloader {
            enable_pad = "ce0";
            busy_pad = "rb0";
            timming_mode = "mode5";
            bch_mode = "bch60_1k";
            t_rea = <0x14>;
            t_rhoh = <0xF>;
            chip_num = <0x1>;
            part_num = <0x0>;
            rb_detect = <0x1>;
            phandle = <0x45>;
        };
        nandnormal {
            enable_pad = "ce0", "ce1";
            busy_pad = "rb0", "rb1";
            timming_mode = "mode5";
            bch_mode = "bch60_1k";
            plane_mode = "twoplane";
            t_rea = <0x14>;
            t_rhoh = <0xF>;
            chip_num = <0x2>;
            part_num = <0x3>;
            partition = <0x47>;
            rb_detect = <0x1>;
            phandle = <0x46>;
        };
        nand_partition {
            phandle = <0x47>;
            logo {
                offset = <0x0 0x0>;
                size = <0x0 0x200000>;
            };
            recovery {
                offset = <0x0 0x0>;
                size = <0x0 0x1000000>;
            };
            boot {
                offset = <0x0 0x0>;
                size = <0x0 0xC00000>;
            };
            system {
                offset = <0x0 0x0>;
                size = <0x0 0xDC40000>;
            };
            data {
                offset = <0xFFFFFFFF 0xFFFFFFFF>;
                size = <0x0 0x0>;
            };
        };
    };
    ethernet@0xc9410000 {
        compatible = "amlogic, gxbb-eth-dwmac";
        reg = <0xC9410000 0x10000 0xC8834540 0x8 0xC8834558 0xC>;
        interrupts = <0x0 0x8 0x1>;
        pinctrl-names = "external_eth_pins";
        pinctrl-0 = <0x48>;
        rst_pin-gpios = <0x11 0xE 0x0>;
        GPIOZ4_pin-gpios = <0x11 0x4 0x0>;
        GPIOZ5_pin-gpios = <0x11 0x5 0x0>;
        mc_val_internal_phy = <0x1800>;
        mc_val_external_phy = <0x1621>;
        cali_val = <0x20000>;
        interrupt-names = "macirq";
        clocks = <0x8 0x34>;
        clock-names = "ethclk81";
        internal_phy = <0x1>;
        phandle = <0xC6>;
    };
    aml-sensor@0 {
        compatible = "amlogic, aml-thermal";
        device_name = "thermal";
        #thermal-sensor-cells = <0x1>;
        phandle = <0x49>;
        cooling_devices {
            cpufreq_cool_cluster0 {
                min_state = <0x124F80>;
                dyn_coeff = <0x8C>;
                cluster_id = <0x0>;
                node_name = "cpufreq_cool0";
                device_type = "cpufreq";
            };
            cpucore_cool_cluster0 {
                min_state = <0x1>;
                dyn_coeff = <0x0>;
                cluster_id = <0x0>;
                node_name = "cpucore_cool0";
                device_type = "cpucore";
            };
            gpufreq_cool {
                min_state = <0x1F4>;
                dyn_coeff = <0x1B5>;
                cluster_id = <0x0>;
                node_name = "gpufreq_cool0";
                device_type = "gpufreq";
            };
            gpucore_cool {
                min_state = <0x1>;
                dyn_coeff = <0x0>;
                cluster_id = <0x0>;
                node_name = "gpucore_cool0";
                device_type = "gpucore";
            };
        };
        cpufreq_cool0 {
            #cooling-cells = <0x2>;
            phandle = <0x4B>;
        };
        cpucore_cool0 {
            #cooling-cells = <0x2>;
            phandle = <0x4C>;
        };
        gpufreq_cool0 {
            #cooling-cells = <0x2>;
            phandle = <0x4D>;
        };
        gpucore_cool0 {
            #cooling-cells = <0x2>;
            phandle = <0x4E>;
        };
    };
    thermal-zones {
        soc_thermal {
            polling-delay = <0x3E8>;
            polling-delay-passive = <0x64>;
            sustainable-power = <0x866>;
            thermal-sensors = <0x49 0x3>;
            trips {
                trip-point@0 {
                    temperature = <0x13880>;
                    hysteresis = <0x3E8>;
                    type = "passive";
                    phandle = <0xC7>;
                };
                trip-point@1 {
                    temperature = <0x15F90>;
                    hysteresis = <0x3E8>;
                    type = "passive";
                    phandle = <0x4A>;
                };
                trip-point@2 {
                    temperature = <0x186A0>;
                    hysteresis = <0x1388>;
                    type = "hot";
                    phandle = <0xC8>;
                };
                trip-point@3 {
                    temperature = <0x3F7A0>;
                    hysteresis = <0x3E8>;
                    type = "critical";
                    phandle = <0xC9>;
                };
            };
            cooling-maps {
                cpufreq_cooling_map {
                    trip = <0x4A>;
                    cooling-device = <0x4B 0x0 0x4>;
                    contribution = <0x400>;
                };
                cpucore_cooling_map {
                    trip = <0x4A>;
                    cooling-device = <0x4C 0x0 0x3>;
                    contribution = <0x400>;
                };
                gpufreq_cooling_map {
                    trip = <0x4A>;
                    cooling-device = <0x4D 0x0 0x4>;
                    contribution = <0x400>;
                };
                gpucore_cooling_map {
                    trip = <0x4A>;
                    cooling-device = <0x4E 0x0 0x2>;
                    contribution = <0x400>;
                };
            };
        };
    };
    dwc3@c9000000 {
        compatible = "synopsys, dwc3";
        reg = <0xC9000000 0x100000>;
        interrupts = <0x0 0x1E 0x4>;
        usb-phy = <0x4F 0x50>;
        cpu-type = "gxl";
        clock-src = "usb3.0";
        phandle = <0xCA>;
    };
    usb2phy@d0078000 {
        compatible = "amlogic, amlogic-new-usb2";
        portnum = <0x3>;
        reg = <0xD0078000 0x80 0xC1104408 0x4>;
        phandle = <0x4F>;
    };
    usb3phy@d0078080 {
        compatible = "amlogic, amlogic-new-usb3";
        portnum = <0x0>;
        reg = <0xD0078080 0x20>;
        interrupts = <0x0 0x10 0x4>;
        otg = <0x1>;
        gpio-vbus-power = "GPIOAO_5";
        gpios = <0x57 0x5 0x0>;
        phandle = <0x50>;
    };
    dwc2_a {
        compatible = "amlogic, dwc2";
        device_name = "dwc2_a";
        reg = <0xC9100000 0x40000>;
        status = "okay";
        interrupts = <0x0 0x1F 0x4>;
        pl-periph-id = <0x0>;
        clock-src = "usb0";
        port-id = <0x0>;
        port-type = <0x2>;
        port-speed = <0x0>;
        port-config = <0x0>;
        port-dma = <0x0>;
        port-id-mode = <0x0>;
        usb-fifo = <0x2D8>;
        cpu-type = "gxl";
        controller-type = <0x3>;
        phy-reg = <0xD0078000>;
        phy-reg-size = <0xA0>;
        clocks = <0x8 0x47 0x8 0x52 0x8 0x43>;
        clock-names = "usb_general", "usb1", "usb1_to_ddr";
    };
    meson-amvideom {
        compatible = "amlogic, amvideom";
        dev_name = "amvideom";
        status = "okay";
        interrupts = <0x0 0x3 0x1>;
        interrupt-names = "vsync";
    };
    vout {
        compatible = "amlogic, vout";
        dev_name = "vout";
        status = "okay";
        fr_auto_policy = <0x0>;
    };
    cvbsout {
        compatible = "amlogic, cvbsout-gxl";
        dev_name = "cvbsout";
        status = "okay";
        clocks = <0x8 0x65 0x8 0x5E 0x8 0x5F 0x8 0x67>;
        clock-names = "venci_top_gate", "venci_0_gate", "venci_1_gate", "vdac_clk_gate";
        performance = <0x1BF0 0x9 0x1B56 0x343 0x1B12 0x8080 0x1B05 0xFD 0x1C59 0xF752 0xFFFF 0x0>;
    };
    amhdmitx {
        compatible = "amlogic, amhdmitx";
        dev_name = "amhdmitx";
        status = "okay";
        vend-data = <0x51>;
        pinctrl-names = "hdmitx_hpd", "hdmitx_ddc";
        pinctrl-0 = <0x52>;
        pinctrl-1 = <0x53>;
        interrupts = <0x0 0x39 0x1>;
        interrupt-names = "hdmitx_hpd";
        ic_type = <0x3>;
        phandle = <0xCB>;
        vend_data {
            vendor_name = "Amlogic";
            vendor_id = <0x0>;
            product_desc = "MBox Meson Ref";
            phandle = <0x51>;
        };
    };
    aocec {
        compatible = "amlogic, amlogic-aocec";
        device_name = "aocec";
        status = "okay";
        vendor_id = <0x0>;
        cec_osd_string = "MBox";
        cec_version = <0x5>;
        port_num = <0x1>;
        arc_port_mask = <0x0>;
        interrupts = <0x0 0xC7 0x1>;
        interrupt-names = "hdmi_aocec";
        pinctrl-names = "default";
        pinctrl-0 = <0x54>;
        reg = <0xC810023C 0x4 0xC8100000 0x200>;
        reg-names = "ao_exit", "ao";
        phandle = <0xCC>;
    };
    sysled {
        compatible = "amlogic, sysled";
        dev_name = "sysled";
        status = "okay";
        led_gpio = <0x11 0x49 0x0>;
        led_active_low = <0x1>;
        led_bicolor = "blue", "red";
    };
    codec_io {
        compatible = "amlogic, codec_io";
        #address-cells = <0x1>;
        #size-cells = <0x1>;
        ranges;
        io_cbus_base {
            reg = <0xC1100000 0x100000>;
        };
        io_dos_base {
            reg = <0xC8820000 0x10000>;
        };
        io_hiubus_base {
            reg = <0xC883C000 0x2000>;
        };
        io_aobus_base {
            reg = <0xC8100000 0x100000>;
        };
        io_vcbus_base {
            reg = <0xD0100000 0x40000>;
        };
        io_dmc_base {
            reg = <0xC8838000 0x400>;
        };
    };
    codec_mm {
        compatible = "amlogic, codec, mm";
        memory-region = <0x55 0x56>;
        dev_name = "codec_mm";
        status = "okay";
    };
    canvas {
        compatible = "amlogic, meson, canvas";
        dev_name = "amlogic-canvas";
        status = "ok";
        reg = <0xC8838000 0x400>;
    };
    mesonstream {
        compatible = "amlogic, codec, streambuf";
        dev_name = "mesonstream";
        status = "okay";
        clocks = <0x8 0x46 0x8 0x35 0x8 0x1A 0x8 0xC 0x8 0xA0 0x8 0xA9 0x8 0xB2>;
        clock-names = "parser_top", "demux", "vdec", "clk_81", "clk_vdec_mux", "clk_hcodec_mux", "clk_hevc_mux";
    };
    vdec {
        compatible = "amlogic, vdec";
        dev_name = "vdec.0";
        status = "okay";
        interrupts = <0x0 0x3 0x1 0x0 0x17 0x1 0x0 0x20 0x1 0x0 0x2B 0x1 0x0 0x2C 0x1 0x0 0x2D 0x1>;
        interrupt-names = "vsync", "demux", "parser", "mailbox_0", "mailbox_1", "mailbox_2";
    };
    gpio_keypad {
        compatible = "amlogic, gpio_keypad";
        status = "okay";
        scan_period = <0x14>;
        detect_mode = <0x0>;
        key_num = <0x2>;
        key_name = "power", "power2";
        key_code = <0x74 0x74>;
        key-gpios = <0x57 0x2 0x0 0x57 0x6 0x0>;
    };
    meson-fb {
        compatible = "amlogic, meson-gxl";
        memory-region = <0x58>;
        dev_name = "meson-fb";
        status = "okay";
        interrupts = <0x0 0x3 0x1 0x0 0x59 0x1>;
        interrupt-names = "viu-vsync", "rdma";
        mem_size = <0x800000 0x1800000 0x100000>;
        display_mode_default = "1080p60hz";
        scale_mode = <0x1>;
        display_size_default = <0x780 0x438 0x780 0xCA8 0x20>;
        logo_addr = "0x3f800000";
    };
    ge2d {
        compatible = "amlogic, ge2d-gxl";
        dev_name = "ge2d";
        status = "okay";
        interrupts = <0x0 0x96 0x1>;
        interrupt-names = "ge2d";
        clocks = <0x8 0xC4 0x8 0x41 0x8 0xC5>;
        clock-names = "clk_vapb_0", "clk_ge2d", "clk_ge2d_gate";
    };
    I2S {
        #sound-dai-cells = <0x0>;
        compatible = "amlogic, aml-i2s-dai";
        clocks = <0x8 0xF 0x8 0xD1 0x8 0x36 0x8 0x37 0x8 0x38 0x8 0x39 0x8 0x3A 0x8 0x3B 0x8 0x3C 0x8 0x3D 0x8 0x3F 0x8 0x68 0x8 0x33>;
        clock-names = "mpll", "mclk", "top_glue", "aud_buf", "i2s_out", "amclk_measure", "aififo2", "aud_mixer", "mixer_reg", "adc", "top_level", "aoclk", "aud_in";
        i2s_pos_sync = <0x0>;
        phandle = <0x65>;
    };
    snd_dmic {
        #sound-dai-cells = <0x0>;
        compatible = "aml, aml_snd_dmic";
        reg = <0xD0042000 0x2000>;
        status = "disabled";
        resets = <0x8 0xD4>;
        reset-names = "pdm";
        pinctrl-names = "audio_dmic";
        pinctrl-0 = <0x59>;
        clocks = <0x8 0xD5 0x8 0xD1>;
        clock-names = "pdm", "mclk";
        phandle = <0xCD>;
    };
    SPDIF {
        #sound-dai-cells = <0x0>;
        compatible = "amlogic, aml-spdif-dai";
        clocks = <0x8 0xE 0x8 0xD9 0x8 0xD1 0x8 0xE0 0x8 0xC 0x8 0x37 0x8 0x69>;
        clock-names = "mpll1", "i958", "mclk", "spdif", "clk_81", "iec958", "iec958_amclk";
        phandle = <0x66>;
    };
    PCM {
        #sound-dai-cells = <0x0>;
        compatible = "amlogic, aml-pcm-dai";
        pinctrl-names = "audio_pcm";
        pinctrl-0 = <0x5A>;
        clocks = <0x8 0xD 0x8 0xDD 0x8 0xDF>;
        clock-names = "mpll0", "pcm_mclk", "pcm_sclk";
        pcm_mode = <0x1>;
        phandle = <0x67>;
    };
    i2s_platform {
        compatible = "amlogic, aml-i2s";
        interrupts = <0x0 0x1D 0x1>;
        phandle = <0x63>;
    };
    pcm_platform {
        compatible = "amlogic, aml-pcm";
        phandle = <0x64>;
    };
    spdif_codec {
        #sound-dai-cells = <0x0>;
        compatible = "amlogic, aml-spdif-codec";
        pinctrl-names = "audio_spdif";
        pinctrl-0 = <0x5B>;
        phandle = <0x69>;
    };
    pcm_codec {
        #sound-dai-cells = <0x0>;
        compatible = "amlogic, pcm2BT-codec";
        phandle = <0x6A>;
    };
    dummy {
        #sound-dai-cells = <0x0>;
        compatible = "amlogic, aml_dummy_codec";
        status = "disable";
        phandle = <0xCE>;
    };
    t9015 {
        #sound-dai-cells = <0x0>;
        compatible = "amlogic, aml_codec_T9015";
        reg = <0xC8832000 0x14>;
        status = "okay";
        phandle = <0x68>;
    };
    aml_sound_meson {
        compatible = "aml, meson-snd-card";
        status = "okay";
        aml-sound-card,format = "i2s";
        aml_sound_card,name = "AML-MESONAUDIO";
        aml,audio-routing = "Ext Spk", "LOUTL", "Ext Spk", "LOUTR";
        mute_gpio-gpios = <0x11 0x15 0x0>;
        mute_inv;
        hp_disable;
        hp_paraments = <0x320 0x12C 0x0 0x5 0x1>;
        pinctrl-names = "audio_i2s";
        pinctrl-0 = <0x5C>;
        cpu_list = <0x5D 0x5E 0x5F>;
        codec_list = <0x60 0x61 0x62>;
        plat_list = <0x63 0x63 0x64>;
        cpudai0 {
            sound-dai = <0x65>;
            phandle = <0x5D>;
        };
        cpudai1 {
            sound-dai = <0x66>;
            phandle = <0x5E>;
        };
        cpudai2 {
            sound-dai = <0x67>;
            phandle = <0x5F>;
        };
        codec0 {
            sound-dai = <0x68>;
            phandle = <0x60>;
        };
        codec1 {
            sound-dai = <0x69>;
            phandle = <0x61>;
        };
        codec2 {
            sound-dai = <0x6A>;
            phandle = <0x62>;
        };
    };
    rdma {
        compatible = "amlogic, meson, rdma";
        dev_name = "amlogic-rdma";
        status = "ok";
        interrupts = <0x0 0x59 0x1>;
        interrupt-names = "rdma";
    };
    amvenc_avc {
        compatible = "amlogic, amvenc_avc";
        dev_name = "amvenc_avc";
        status = "okay";
        interrupts = <0x0 0x2D 0x1>;
        interrupt-names = "mailbox_2";
    };
    hevc_enc {
        compatible = "cnm, HevcEnc";
        dev_name = "HevcEnc";
        status = "okay";
        interrupts = <0x0 0xBB 0x1>;
        interrupt-names = "wave420l_irq";
        #address-cells = <0x1>;
        #size-cells = <0x1>;
        ranges;
        io_reg_base {
            reg = <0xC8810000 0x4000>;
        };
    };
    picdec {
        compatible = "amlogic, picdec";
        memory-region = <0x6B>;
        dev_name = "picdec";
        status = "okay";
    };
    ppmgr {
        compatible = "amlogic, ppmgr";
        memory-region = <0x6C>;
        dev_name = "ppmgr";
        status = "okay";
    };
    deinterlace {
        compatible = "amlogic, deinterlace";
        status = "okay";
        flag_cma = <0x1>;
        memory-region = <0x6D>;
        interrupts = <0x0 0x2E 0x1 0x0 0x6 0x1>;
        interrupt-names = "de_irq", "timerc";
        buffer-size = <0x2FD000>;
        hw-version = <0x2>;
    };
    ionvideo {
        compatible = "amlogic, ionvideo";
        dev_name = "ionvideo";
        status = "okay";
    };
    amlvideo {
        compatible = "amlogic, amlvideo";
        dev_name = "amlvideo";
        status = "okay";
    };
    amlvideo2_0 {
        compatible = "amlogic, amlvideo2";
        dev_name = "amlvideo2";
        status = "okay";
        amlvideo2_id = <0x0>;
        cma_mode = <0x1>;
    };
    amlvideo2_1 {
        compatible = "amlogic, amlvideo2";
        dev_name = "amlvideo2";
        status = "okay";
        amlvideo2_id = <0x1>;
        cma_mode = <0x1>;
    };
    vdin0 {
        compatible = "amlogic, vdin";
        dev_name = "vdin0";
        status = "ok";
        reserve-iomap = "true";
        flag_cma = <0x1>;
        cma_size = <0x10>;
        interrupts = <0x0 0x53 0x1>;
        rdma-irq = <0x2>;
        vdin_id = <0x0>;
        tv_bit_mode = <0x1>;
    };
    vdin1 {
        compatible = "amlogic, vdin";
        memory-region = <0x6E>;
        dev_name = "vdin1";
        status = "ok";
        reserve-iomap = "true";
        flag_cma = <0x0>;
        interrupts = <0x0 0x55 0x1>;
        rdma-irq = <0x4>;
        vdin_id = <0x1>;
        tv_bit_mode = <0x1>;
    };
    amlvecm {
        compatible = "amlogic, vecm";
        dev_name = "aml_vecm";
        status = "okay";
        gamma_en = <0x0>;
        wb_en = <0x0>;
        cm_en = <0x0>;
        cfg_en_osd_100 = <0x1>;
        tx_op_color_primary = <0x0>;
    };
    unifykey {
        compatible = "amlogic, unifykey";
        status = "ok";
        unifykey-num = <0x11>;
        unifykey-index-0 = <0x6F>;
        unifykey-index-1 = <0x70>;
        unifykey-index-2 = <0x71>;
        unifykey-index-3 = <0x72>;
        unifykey-index-4 = <0x73>;
        unifykey-index-5 = <0x74>;
        unifykey-index-6 = <0x75>;
        unifykey-index-7 = <0x76>;
        unifykey-index-8 = <0x77>;
        unifykey-index-9 = <0x78>;
        unifykey-index-10 = <0x79>;
        unifykey-index-11 = <0x7A>;
        unifykey-index-12 = <0x7B>;
        unifykey-index-13 = <0x7C>;
        unifykey-index-14 = <0x7D>;
        unifykey-index-15 = <0x7E>;
        unifykey-index-16 = <0x7F>;
        key_0 {
            key-name = "usid";
            key-device = "normal";
            key-permit = "read", "write", "del";
            phandle = <0x6F>;
        };
        key_1 {
            key-name = "mac";
            key-device = "normal";
            key-permit = "read", "write", "del";
            phandle = <0x70>;
        };
        key_2 {
            key-name = "hdcp";
            key-device = "secure";
            key-type = "sha1";
            key-permit = "read", "write", "del";
            phandle = <0x71>;
        };
        key_3 {
            key-name = "secure_boot_set";
            key-device = "efuse";
            key-permit = "write";
            phandle = <0x72>;
        };
        key_4 {
            key-name = "mac_bt";
            key-device = "normal";
            key-permit = "read", "write", "del";
            key-type = "mac";
            phandle = <0x73>;
        };
        key_5 {
            key-name = "mac_wifi";
            key-device = "normal";
            key-permit = "read", "write", "del";
            key-type = "mac";
            phandle = <0x74>;
        };
        key_6 {
            key-name = "hdcp2_tx";
            key-device = "normal";
            key-permit = "read", "write", "del";
            phandle = <0x75>;
        };
        key_7 {
            key-name = "hdcp2_rx";
            key-device = "normal";
            key-permit = "read", "write", "del";
            phandle = <0x76>;
        };
        key_8 {
            key-name = "widevinekeybox";
            key-device = "secure";
            key-permit = "read", "write", "del";
            phandle = <0x77>;
        };
        key_9 {
            key-name = "deviceid";
            key-device = "normal";
            key-permit = "read", "write", "del";
            phandle = <0x78>;
        };
        key_10 {
            key-name = "hdcp22_fw_private";
            key-device = "secure";
            key-permit = "read", "write", "del";
            phandle = <0x79>;
        };
        key_11 {
            key-name = "PlayReadykeybox25";
            key-device = "secure";
            key-permit = "read", "write", "del";
            phandle = <0x7A>;
        };
        key_12 {
            key-name = "prpubkeybox";
            key-device = "secure";
            key-permit = "read", "write", "del";
            phandle = <0x7B>;
        };
        key_13 {
            key-name = "prprivkeybox";
            key-device = "secure";
            key-permit = "read", "write", "del";
            phandle = <0x7C>;
        };
        key_14 {
            key-name = "attestationkeybox";
            key-device = "secure";
            key-permit = "read", "write", "del";
            phandle = <0x7D>;
        };
        key_15 {
            key-name = "region_code";
            key-device = "normal";
            key-permit = "read", "write", "del";
            phandle = <0x7E>;
        };
        key_16 {
            key-name = "netflix_mgkid";
            key-device = "secure";
            key-permit = "read", "write", "del";
            phandle = <0x7F>;
        };
    };
    __symbols__ {
        gpu = "/mali@d00c0000";
        clk125_cfg = "/mali@d00c0000/clk125_cfg";
        clk250_cfg = "/mali@d00c0000/clk250_cfg";
        clk285_cfg = "/mali@d00c0000/clk285_cfg";
        clk400_cfg = "/mali@d00c0000/clk400_cfg";
        clk500_cfg = "/mali@d00c0000/clk500_cfg";
        clk666_cfg = "/mali@d00c0000/clk666_cfg";
        clk750_cfg = "/mali@d00c0000/clk750_cfg";
        clk800_cfg = "/mali@d00c0000/clk800_cfg";
        cpus = "/cpus";
        cluster0 = "/cpus/cpu-map/cluster0";
        CPU0 = "/cpus/cpu@0";
        CPU1 = "/cpus/cpu@1";
        CPU2 = "/cpus/cpu@2";
        CPU3 = "/cpus/cpu@3";
        SYSTEM_SLEEP_0 = "/cpus/idle-states/system-sleep-0";
        gic = "/interrupt-controller@2c001000";
        meson_suspend = "/pm";
        wdt = "/watchdog@0xffd0f0d0";
        mailbox = "/mhu@c883c400";
        scpi_dvfs = "/scpi_clocks/scpi_clocks@0";
        xtal = "/xtal-clk";
        spicc = "/@c1108d80";
        uart_AO = "/serial@c81004c0";
        uart_A = "/serial@c11084c0";
        uart_B = "/serial@c11084dc";
        uart_C = "/serial@c1108700";
        uart_AO_B = "/serial@c81004e0";
        pinctrl_aobus = "/pinctrl@14";
        gpio_ao = "/pinctrl@14/bank@14";
        remote_pins = "/pinctrl@14/remote_pin";
        sd_to_ao_uart_clr_pins = "/pinctrl@14/sd_to_ao_uart_clr_pins";
        sd_to_ao_uart_pins = "/pinctrl@14/sd_to_ao_uart_pins";
        ao_uart_pins = "/pinctrl@14/ao_uart";
        ao_b_uart_pins = "/pinctrl@14/ao_b_uart";
        ao_i2c_master = "/pinctrl@14/ao_i2c";
        hdmitx_aocec = "/pinctrl@14/hdmitx_aocec";
        hdmitx_eecec = "/pinctrl@14/hdmitx_eecec";
        pinctrl_periphs = "/pinctrl@4b0";
        gpio = "/pinctrl@4b0/bank@4b0";
        external_eth_pins = "/pinctrl@4b0/external_eth_pins";
        jtag_apao_pins = "/pinctrl@4b0/jtag_apao_pin";
        jtag_apee_pins = "/pinctrl@4b0/jtag_apee_pin";
        a_uart_pins = "/pinctrl@4b0/a_uart";
        b_uart_pins = "/pinctrl@4b0/b_uart";
        c_uart_pins = "/pinctrl@4b0/c_uart";
        wifi_32k_pins = "/pinctrl@4b0/wifi_32k_pins";
        ao_to_sd_uart_clr_pins = "/pinctrl@4b0/ao_to_sd_uart_clr_pins";
        sd_1bit_pins = "/pinctrl@4b0/sd_1bit_pins";
        ao_to_sd_uart_pins = "/pinctrl@4b0/ao_to_sd_uart_pins";
        emmc_clk_cmd_pins = "/pinctrl@4b0/emmc_clk_cmd_pins";
        emmc_conf_pull_up = "/pinctrl@4b0/emmc_conf_pull_up";
        emmc_conf_pull_done = "/pinctrl@4b0/emmc_conf_pull_done";
        sd_clk_cmd_pins = "/pinctrl@4b0/sd_clk_cmd_pins";
        sd_all_pins = "/pinctrl@4b0/sd_all_pins";
        sdio_clk_cmd_pins = "/pinctrl@4b0/sdio_clk_cmd_pins";
        sdio_all_pins = "/pinctrl@4b0/sdio_all_pins";
        sd_iso7816_pins = "/pinctrl@4b0/sd_iso7816_pins";
        nand_pulldown = "/pinctrl@4b0/nand_pulldown";
        nand_pullup = "/pinctrl@4b0/nand_pullup";
        all_nand_pins = "/pinctrl@4b0/all_nand_pins";
        nand_cs_pins = "/pinctrl@4b0/nand_cs";
        hdmitx_hpd = "/pinctrl@4b0/hdmitx_hpd";
        hdmitx_ddc = "/pinctrl@4b0/hdmitx_ddc";
        a_i2c_master = "/pinctrl@4b0/a_i2c";
        b_i2c_master = "/pinctrl@4b0/b_i2c";
        c_i2c_master = "/pinctrl@4b0/c_i2c";
        c_i2c_master_pin1 = "/pinctrl@4b0/c_i2c_pin1";
        d_i2c_master = "/pinctrl@4b0/d_i2c";
        spicc_pulldown_z11z12z13 = "/pinctrl@4b0/spicc_pulldown_z11z12z13";
        spicc_pullup_z11z12z13 = "/pinctrl@4b0/spicc_pullup_z11z12z13";
        spicc_pulldown_x8x9x11 = "/pinctrl@4b0/spicc_pulldown_x8x9x11";
        spicc_pullup_x8x9x11 = "/pinctrl@4b0/spicc_pullup_x8x9x11";
        audio_i2s_pins = "/pinctrl@4b0/audio_i2s";
        audio_spdif_pins = "/pinctrl@4b0/audio_spdif";
        audio_spdif_in_pins = "/pinctrl@4b0/audio_spdif_in";
        audio_spdif_in_1_pins = "/pinctrl@4b0/audio_spdif_in_1";
        audio_pcm_pins = "/pinctrl@4b0/audio_pcm";
        aml_dmic_pins = "/pinctrl@4b0/audio_dmic";
        dvb_p_ts0_pins = "/pinctrl@4b0/dvb_p_ts0_pins";
        dvb_s_ts0_pins = "/pinctrl@4b0/dvb_s_ts0_pins";
        lcd_ttl_rgb_6bit_on_pins = "/pinctrl@4b0/lcd_ttl_rgb_6bit_on";
        lcd_ttl_rgb_6bit_off_pins = "/pinctrl@4b0/lcd_ttl_rgb_6bit_off";
        lcd_ttl_rgb_8bit_on_pins = "/pinctrl@4b0/lcd_ttl_rgb_8bit_on";
        lcd_ttl_rgb_8bit_off_pins = "/pinctrl@4b0/lcd_ttl_rgb_8bit_off";
        lcd_ttl_de_on_pins = "/pinctrl@4b0/lcd_ttl_de_on_pin";
        lcd_ttl_hvsync_on_pins = "/pinctrl@4b0/lcd_ttl_hvsync_on_pin";
        lcd_ttl_de_hvsync_on_pins = "/pinctrl@4b0/lcd_ttl_de_hvsync_on_pin";
        lcd_ttl_de_hvsync_off_pins = "/pinctrl@4b0/lcd_ttl_de_hvsync_off_pin";
        cbus = "/soc/cbus@c1100000";
        gpio_intc = "/soc/cbus@c1100000/interrupt-controller@9880";
        i2c0 = "/soc/cbus@c1100000/i2c@8500";
        i2c1 = "/soc/cbus@c1100000/i2c@87c0";
        i2c2 = "/soc/cbus@c1100000/i2c@87e0";
        i2c3 = "/soc/cbus@c1100000/i2c@8d20";
        reset = "/soc/cbus@c1100000/reset-controller@4404";
        aobus = "/soc/aobus@c8100000";
        i2c_AO = "/soc/aobus@c8100000/i2c@0500";
        periphs = "/soc/periphs@c8834000";
        hiubus = "/soc/hiubus@c883c000";
        clkc = "/soc/hiubus@c883c000/clock-controller@0";
        apb = "/soc/apb@d0000000";
        defendkey = "/defendkey";
        audio_data = "/audio_data";
        saradc = "/saradc";
        efuse = "/efuse";
        efusekey = "/efusekey";
        key_0 = "/efusekey/key_0";
        key_1 = "/efusekey/key_1";
        key_2 = "/efusekey/key_2";
        key_3 = "/efusekey/key_3";
        remote = "/rc@c8100580";
        custom_maps = "/custom_maps";
        map_0 = "/custom_maps/map_0";
        map_1 = "/custom_maps/map_1";
        map_2 = "/custom_maps/map_2";
        pwm_ab = "/pwm@c1108550";
        pwm_cd = "/pwm@c1108640";
        pwm_ef = "/pwm@c11086c0";
        pwm_aoab = "/pwm@c8100550";
        partitions = "/partitions";
        logo = "/partitions/logo";
        recovery = "/partitions/recovery";
        misc = "/partitions/misc";
        dtbo = "/partitions/dtbo";
        cri_data = "/partitions/cri_data";
        rsv = "/partitions/rsv";
        metadata = "/partitions/metadata";
        vbmeta = "/partitions/vbmeta";
        param = "/partitions/param";
        boot = "/partitions/boot";
        tee = "/partitions/tee";
        vendor = "/partitions/vendor";
        odm = "/partitions/odm";
        system = "/partitions/system";
        product = "/partitions/product";
        cache = "/partitions/cache";
        data = "/partitions/data";
        secmon_reserved = "/reserved-memory/linux,secmon";
        secos_reserved = "/reserved-memory/linux,secos";
        logo_reserved = "/reserved-memory/linux,meson-fb";
        codec_mm_cma = "/reserved-memory/linux,codec_mm_cma";
        di_cma_reserved = "/reserved-memory/linux,di_cma";
        ion_reserved = "/reserved-memory/linux,ion-dev";
        vdin1_cma_reserved = "/reserved-memory/linux,vdin1_cma";
        ppmgr_reserved = "/reserved-memory/linux,ppmgr";
        picdec_cma_reserved = "/reserved-memory/linux,picdec";
        codec_mm_reserved = "/reserved-memory/linux,codec_mm_reserved";
        amlogic_battery = "/dummy-battery";
        amlogic_charger = "/dummy-charger";
        wifi_pwm_conf = "/wifi_pwm_conf";
        sd_emmc_c = "/emmc@d0074000";
        sd_emmc_b = "/sd@d0072000";
        sd_emmc_a = "/sdio@d0070000";
        bootloader = "/mtd_nand/bootloader";
        nandnormal = "/mtd_nand/nandnormal";
        nand_partitions = "/mtd_nand/nand_partition";
        ethmac = "/ethernet@0xc9410000";
        aml_sensor0 = "/aml-sensor@0";
        cpufreq_cool0 = "/aml-sensor@0/cpufreq_cool0";
        cpucore_cool0 = "/aml-sensor@0/cpucore_cool0";
        gpufreq_cool0 = "/aml-sensor@0/gpufreq_cool0";
        gpucore_cool0 = "/aml-sensor@0/gpucore_cool0";
        switch_on = "/thermal-zones/soc_thermal/trips/trip-point@0";
        control = "/thermal-zones/soc_thermal/trips/trip-point@1";
        hot = "/thermal-zones/soc_thermal/trips/trip-point@2";
        critical = "/thermal-zones/soc_thermal/trips/trip-point@3";
        dwc3 = "/dwc3@c9000000";
        usb2_phy = "/usb2phy@d0078000";
        usb3_phy = "/usb3phy@d0078080";
        amhdmitx = "/amhdmitx";
        vend_data = "/amhdmitx/vend_data";
        aocec = "/aocec";
        i2s_dai = "/I2S";
        dmic = "/snd_dmic";
        spdif_dai = "/SPDIF";
        pcm_dai = "/PCM";
        i2s_plat = "/i2s_platform";
        pcm_plat = "/pcm_platform";
        spdif_codec = "/spdif_codec";
        pcm_codec = "/pcm_codec";
        dummy_codec = "/dummy";
        amlogic_codec = "/t9015";
        cpudai0 = "/aml_sound_meson/cpudai0";
        cpudai1 = "/aml_sound_meson/cpudai1";
        cpudai2 = "/aml_sound_meson/cpudai2";
        codec0 = "/aml_sound_meson/codec0";
        codec1 = "/aml_sound_meson/codec1";
        codec2 = "/aml_sound_meson/codec2";
        keysn_0 = "/unifykey/key_0";
        keysn_1 = "/unifykey/key_1";
        keysn_2 = "/unifykey/key_2";
        keysn_3 = "/unifykey/key_3";
        keysn_4 = "/unifykey/key_4";
        keysn_5 = "/unifykey/key_5";
        keysn_6 = "/unifykey/key_6";
        keysn_7 = "/unifykey/key_7";
        keysn_8 = "/unifykey/key_8";
        keysn_9 = "/unifykey/key_9";
        keysn_10 = "/unifykey/key_10";
        keysn_11 = "/unifykey/key_11";
        keysn_12 = "/unifykey/key_12";
        keysn_13 = "/unifykey/key_13";
        keysn_14 = "/unifykey/key_14";
        keysn_15 = "/unifykey/key_15";
        keysn_16 = "/unifykey/key_16";
    };
};
